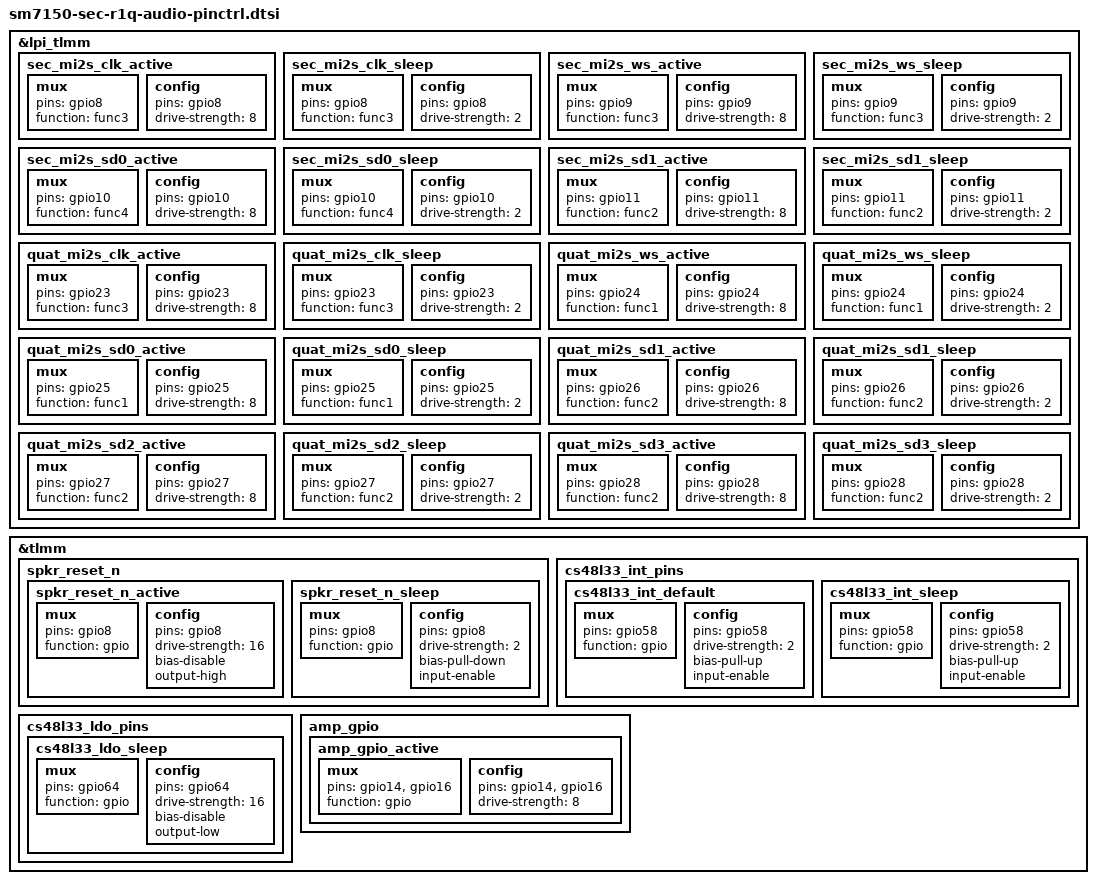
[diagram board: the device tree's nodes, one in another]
&lpi_tlmm  {
	sec_mi2s_clk_active: sec_mi2s_clk_active {
		mux {
			pins = "gpio8";
			function = "func3";
		};
		config {
			pins = "gpio8";
			drive-strength = <8>;
		};
	};
	sec_mi2s_clk_sleep: sec_mi2s_clk_sleep {
		mux {
			pins = "gpio8";
			function = "func3";
		};
		config {
			pins = "gpio8";
			drive-strength = <2>;
		};
	};

	sec_mi2s_ws_active: sec_mi2s_ws_active {
		mux {
			pins = "gpio9";
			function = "func3";
		};
		config {
			pins = "gpio9";
			drive-strength = <8>;
		};
	};

	sec_mi2s_ws_sleep: sec_mi2s_ws_sleep {
		mux {
			pins = "gpio9";
			function = "func3";
		};
		config {
			pins = "gpio9";
			drive-strength = <2>;
		};
	};

	sec_mi2s_sd0_active: sec_mi2s_sd0_active {
		mux {
			pins = "gpio10";
			function = "func4";
		};

		config {
			pins = "gpio10";
			drive-strength = <8>;
		};
	};

	sec_mi2s_sd0_sleep: sec_mi2s_sd0_sleep {
		mux {
			pins = "gpio10";
			function = "func4";
		};
		config {
			pins = "gpio10";
			drive-strength = <2>;
		};
	};

	sec_mi2s_sd1_active: sec_mi2s_sd1_active {
		mux {
			pins = "gpio11";
			function = "func2";
		};
		config {
			pins = "gpio11";
			drive-strength = <8>;
		};
	};

	sec_mi2s_sd1_sleep: sec_mi2s_sd1_sleep {
		mux {
			pins = "gpio11";
			function = "func2";
		};
		config {
			pins = "gpio11";
			drive-strength = <2>;
		};
	};

	/*Quat MI2S*/
	quat_mi2s_clk_active: quat_mi2s_clk_active {
		mux {
			pins = "gpio23";
			function = "func3";
		};

		config {
			pins = "gpio23";
			drive-strength = <8>;
		};
	};

	quat_mi2s_clk_sleep: quat_mi2s_clk_sleep {
		mux {
			pins = "gpio23";
			function = "func3";
		};

		config {
			pins = "gpio23";
			drive-strength = <2>;
		};
	};

	quat_mi2s_ws_active: quat_mi2s_ws_active {
		mux {
			pins = "gpio24";
			function = "func1";
		};

		config {
			pins = "gpio24";
			drive-strength = <8>;
		};
	};

	quat_mi2s_ws_sleep: quat_mi2s_ws_sleep {
		mux {
			pins = "gpio24";
			function = "func1";
		};

		config {
			pins = "gpio24";
			drive-strength = <2>;
		};
	};

	quat_mi2s_sd0_active: quat_mi2s_sd0_active {
		mux {
			pins = "gpio25";
			function = "func1";
		};

		config {
			pins = "gpio25";
			drive-strength = <8>;
		};
	};

	quat_mi2s_sd0_sleep: quat_mi2s_sd0_sleep {
		mux {
			pins = "gpio25";
			function = "func1";
		};

		config {
			pins = "gpio25";
			drive-strength = <2>;
		};
	};

	quat_mi2s_sd1_active: quat_mi2s_sd1_active {
		mux {
			pins = "gpio26";
			function = "func2";
		};

		config {
			pins = "gpio26";
			drive-strength = <8>;
		};
	};

	quat_mi2s_sd1_sleep: quat_mi2s_sd1_sleep {
		mux {
			pins = "gpio26";
			function = "func2";
		};

		config {
			pins = "gpio26";
			drive-strength = <2>;
		};
	};
	quat_mi2s_sd2_active: quat_mi2s_sd2_active {
		mux {
			pins = "gpio27";
			function = "func2";
		};

		config {
			pins = "gpio27";
			drive-strength = <8>;
		};
	};

	quat_mi2s_sd2_sleep: quat_mi2s_sd2_sleep {
		mux {
			pins = "gpio27";
			function = "func2";
		};

		config {
			pins = "gpio27";
			drive-strength = <2>;
		};
	};
	quat_mi2s_sd3_active: quat_mi2s_sd3_active {
		mux {
			pins = "gpio28";
			function = "func2";
		};

		config {
			pins = "gpio28";
			drive-strength = <8>;
		};
	};

	quat_mi2s_sd3_sleep: quat_mi2s_sd3_sleep {
		mux {
			pins = "gpio28";
			function = "func2";
		};

		config {
			pins = "gpio28";
			drive-strength = <2>;
		};
	};
};

&tlmm {
	/* WSA speaker reset pins */
	spkr_reset_n {
		spkr_reset_n_active: spkr_reset_n_active {
			mux {
				pins = "gpio8";
				function = "gpio";
			};

			config {
				pins = "gpio8";
				drive-strength = <16>;   /* 16 mA */
				bias-disable;
				output-high;
			};
		};

		spkr_reset_n_sleep: spkr_reset_n_sleep {
			mux {
				pins = "gpio8";
				function = "gpio";
			};

			config {
				pins = "gpio8";
				drive-strength = <2>;   /* 2 mA */
				bias-pull-down;
				input-enable;
			};
		};
	};

	/* Cooke int pins */
	cs48l33_int_pins: cs48l33_int_pins {
		cs48l33_int_default: cs48l33_int_default {
			mux {
				pins = "gpio58";
				function = "gpio";
			};

			config {
				pins = "gpio58";
				drive-strength = <2>;
				bias-pull-up;
				input-enable;
			};
		};

		cs48l33_int_sleep: cs48l33_int_sleep {
			mux {
				pins = "gpio58";
				function = "gpio";
			};

			config {
				pins = "gpio58";
				drive-strength = <2>;
				bias-pull-up;
				input-enable;
			};
		};
	};

	/* Cooke ldo pins */
	cs48l33_ldo_pins: cs48l33_ldo_pins {
		cs48l33_ldo_sleep: cs48l33_ldo_sleep {
			mux {
				pins = "gpio64";
				function = "gpio";
			};

			config {
				pins = "gpio64";
				drive-strength = <16>;   /* 16 mA */
				bias-disable;
				output-low;
			};
		};
	};

	amp_gpio {
		amp_gpio_active: amp_gpio_active {
			mux {
				pins = "gpio14","gpio16";
				function = "gpio";
			};
			config {
				pins = "gpio14","gpio16";
				drive-strength = <8>;
			};
		};
	};
};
